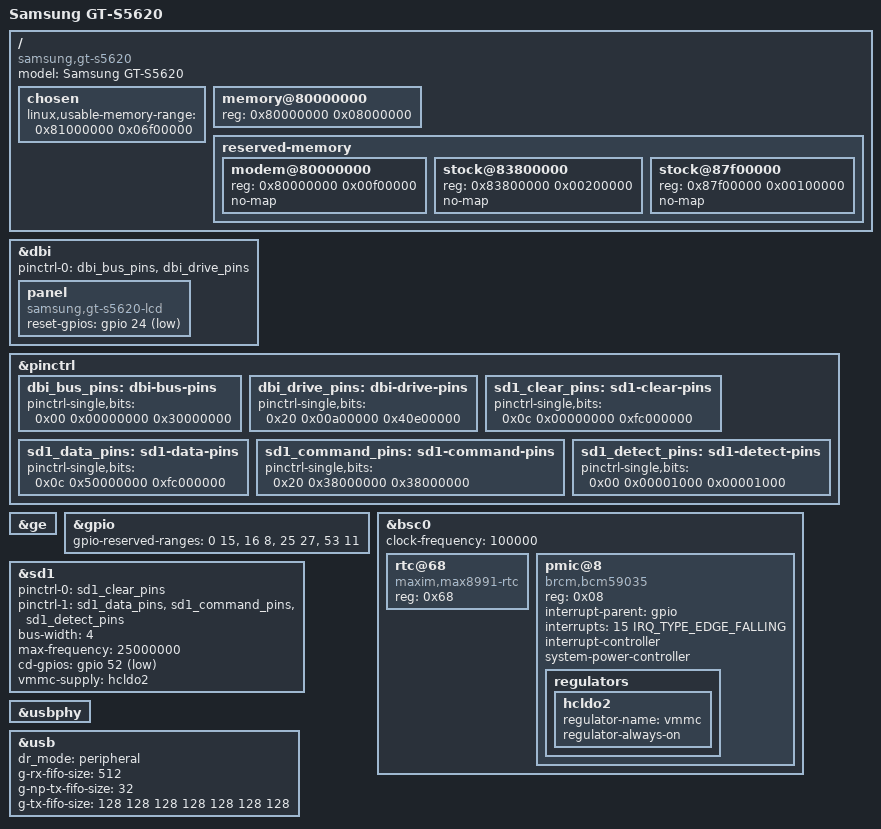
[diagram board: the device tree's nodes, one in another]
// SPDX-License-Identifier: (GPL-2.0-only OR BSD-2-Clause)
/dts-v1/;

#include "bcm2153.dtsi"
#include <dt-bindings/gpio/gpio.h>

/ {
	model = "Samsung GT-S5620";
	compatible = "samsung,gt-s5620", "brcm,bcm2153";

	chosen {
		linux,usable-memory-range = <0x81000000 0x06f00000>;
	};

	memory@80000000 {
		device_type = "memory";
		reg = <0x80000000 0x08000000>;
	};

	reserved-memory {
		#address-cells = <1>;
		#size-cells = <1>;
		ranges;

		modem@80000000 {
			reg = <0x80000000 0x00f00000>;
			no-map;
		};

		stock@83800000 {
			reg = <0x83800000 0x00200000>;
			no-map;
		};

		stock@87f00000 {
			reg = <0x87f00000 0x00100000>;
			no-map;
		};
	};
};

&dbi {
	status = "okay";
	pinctrl-names = "default";
	pinctrl-0 = <&dbi_bus_pins &dbi_drive_pins>;

	panel {
		compatible = "samsung,gt-s5620-lcd";
		reset-gpios = <&gpio 24 GPIO_ACTIVE_LOW>;
	};
};

&pinctrl {
	status = "okay";

	dbi_bus_pins: dbi-bus-pins {
		pinctrl-single,bits = <0x00 0x00000000 0x30000000>;
	};

	dbi_drive_pins: dbi-drive-pins {
		pinctrl-single,bits = <0x20 0x00a00000 0x40e00000>;
	};

	sd1_clear_pins: sd1-clear-pins {
		pinctrl-single,bits = <0x0c 0x00000000 0xfc000000>;
	};

	sd1_data_pins: sd1-data-pins {
		pinctrl-single,bits = <0x0c 0x50000000 0xfc000000>;
	};

	sd1_command_pins: sd1-command-pins {
		pinctrl-single,bits = <0x20 0x38000000 0x38000000>;
	};

	sd1_detect_pins: sd1-detect-pins {
		pinctrl-single,bits = <0x00 0x00001000 0x00001000>;
	};
};

&ge {
	status = "okay";
};

&gpio {
	gpio-reserved-ranges = <0 15>, <16 8>, <25 27>, <53 11>;
	status = "okay";
};

&bsc0 {
	status = "okay";
	clock-frequency = <100000>;

	rtc@68 {
		compatible = "maxim,max8991-rtc";
		reg = <0x68>;
	};

	pmic@8 {
		compatible = "brcm,bcm59035";
		reg = <0x08>;
		interrupt-parent = <&gpio>;
		interrupts = <15 IRQ_TYPE_EDGE_FALLING>;
		interrupt-controller;
		#interrupt-cells = <1>;
		system-power-controller;

		regulators {
			hcldo2: hcldo2 {
				regulator-name = "vmmc";
				regulator-always-on;
			};
		};
	};
};

&sd1 {
	pinctrl-names = "powered-init", "powered";
	pinctrl-0 = <&sd1_clear_pins>;
	pinctrl-1 = <&sd1_data_pins &sd1_command_pins
		     &sd1_detect_pins>;
	bus-width = <4>;
	max-frequency = <25000000>;
	cd-gpios = <&gpio 52 GPIO_ACTIVE_LOW>;
	vmmc-supply = <&hcldo2>;
	status = "okay";
};

&usbphy {
	status = "okay";
};

&usb {
	dr_mode = "peripheral";
	g-rx-fifo-size = <512>;
	g-np-tx-fifo-size = <32>;
	g-tx-fifo-size = <128 128 128 128 128 128 128>;
	status = "okay";
};
